# ESP32C3 register map
File version: 1.0
CPU: RISC-V RV32IMC single-core 1, little endian, no MPU, FPU, 3 interrupt priority bits
Registers are 32-bit, read-write, reset 0x0 unless marked. A register's access mark holds for its fields unless they carry their own. Offsets are from the block's base; [hi:lo] are bit positions; {n}, {i} and the like mark numbered series.

## I2C
Base 0x00000000
0x00 I2C_SCL_LOW_PERIOD
  [8:0] I2C_SCL_LOW_PERIOD
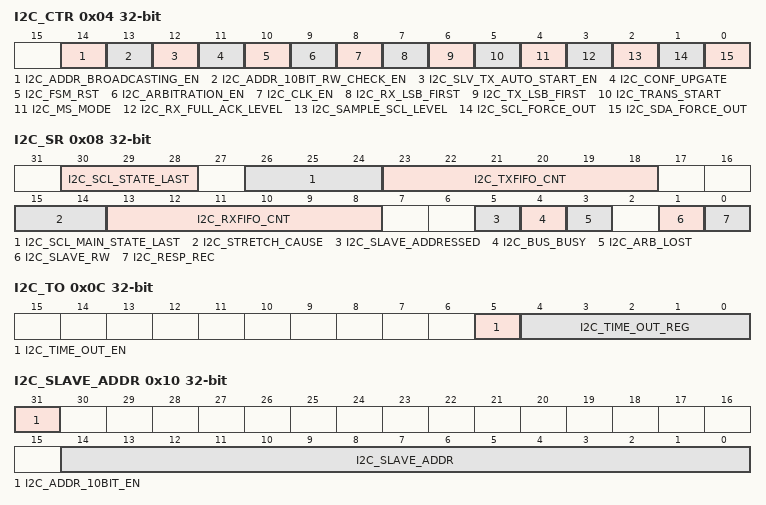
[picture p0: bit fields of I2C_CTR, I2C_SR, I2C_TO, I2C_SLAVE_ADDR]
0x04 I2C_CTR access per field
  [14] I2C_ADDR_BROADCASTING_EN rw, [13] I2C_ADDR_10BIT_RW_CHECK_EN rw, [12] I2C_SLV_TX_AUTO_START_EN rw, [11] I2C_CONF_UPGATE wo, [10] I2C_FSM_RST wo, [9] I2C_ARBITRATION_EN rw, [8] I2C_CLK_EN rw, [7] I2C_RX_LSB_FIRST rw, [6] I2C_TX_LSB_FIRST rw, [5] I2C_TRANS_START wo, [4] I2C_MS_MODE rw, [3] I2C_RX_FULL_ACK_LEVEL rw, [2] I2C_SAMPLE_SCL_LEVEL rw, [1] I2C_SCL_FORCE_OUT rw, [0] I2C_SDA_FORCE_OUT rw
0x08 I2C_SR ro
  [30:28] I2C_SCL_STATE_LAST, [26:24] I2C_SCL_MAIN_STATE_LAST, [23:18] I2C_TXFIFO_CNT, [15:14] I2C_STRETCH_CAUSE, [13:8] I2C_RXFIFO_CNT, [5] I2C_SLAVE_ADDRESSED, [4] I2C_BUS_BUSY, [3] I2C_ARB_LOST, [1] I2C_SLAVE_RW, [0] I2C_RESP_REC
0x0C I2C_TO
  [5] I2C_TIME_OUT_EN, [4:0] I2C_TIME_OUT_REG
0x10 I2C_SLAVE_ADDR
  [31] I2C_ADDR_10BIT_EN, [14:0] I2C_SLAVE_ADDR
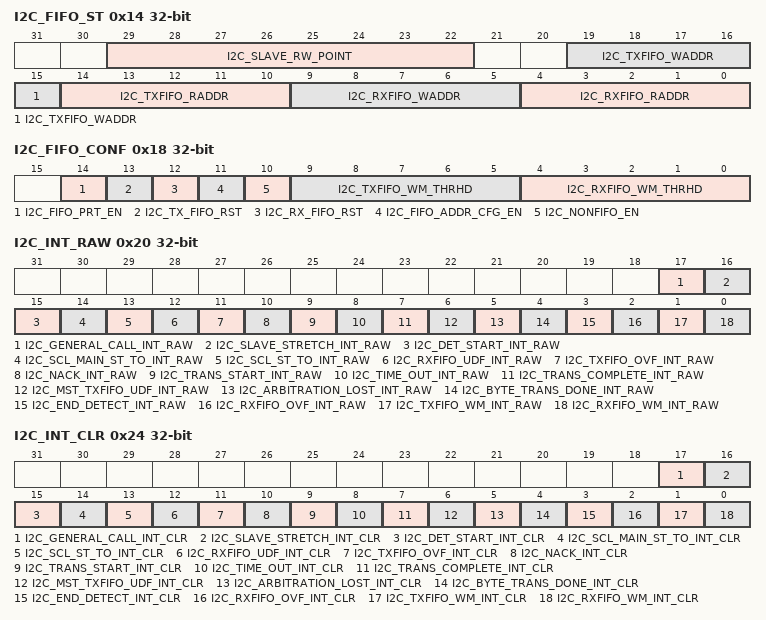
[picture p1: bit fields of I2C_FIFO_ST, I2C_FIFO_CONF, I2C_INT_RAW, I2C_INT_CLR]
0x14 I2C_FIFO_ST ro
  [29:22] I2C_SLAVE_RW_POINT, [19:15] I2C_TXFIFO_WADDR, [14:10] I2C_TXFIFO_RADDR, [9:5] I2C_RXFIFO_WADDR, [4:0] I2C_RXFIFO_RADDR
0x18 I2C_FIFO_CONF
  [14] I2C_FIFO_PRT_EN, [13] I2C_TX_FIFO_RST, [12] I2C_RX_FIFO_RST, [11] I2C_FIFO_ADDR_CFG_EN, [10] I2C_NONFIFO_EN, [9:5] I2C_TXFIFO_WM_THRHD, [4:0] I2C_RXFIFO_WM_THRHD
0x1C I2C_DATA ro
  [7:0] I2C_FIFO_RDATA
0x20 I2C_INT_RAW
  [17] I2C_GENERAL_CALL_INT_RAW, [16] I2C_SLAVE_STRETCH_INT_RAW, [15] I2C_DET_START_INT_RAW, [14] I2C_SCL_MAIN_ST_TO_INT_RAW, [13] I2C_SCL_ST_TO_INT_RAW, [12] I2C_RXFIFO_UDF_INT_RAW, [11] I2C_TXFIFO_OVF_INT_RAW, [10] I2C_NACK_INT_RAW, [9] I2C_TRANS_START_INT_RAW, [8] I2C_TIME_OUT_INT_RAW, [7] I2C_TRANS_COMPLETE_INT_RAW, [6] I2C_MST_TXFIFO_UDF_INT_RAW, [5] I2C_ARBITRATION_LOST_INT_RAW, [4] I2C_BYTE_TRANS_DONE_INT_RAW, [3] I2C_END_DETECT_INT_RAW, [2] I2C_RXFIFO_OVF_INT_RAW, [1] I2C_TXFIFO_WM_INT_RAW, [0] I2C_RXFIFO_WM_INT_RAW
0x24 I2C_INT_CLR wo
  [17] I2C_GENERAL_CALL_INT_CLR, [16] I2C_SLAVE_STRETCH_INT_CLR, [15] I2C_DET_START_INT_CLR, [14] I2C_SCL_MAIN_ST_TO_INT_CLR, [13] I2C_SCL_ST_TO_INT_CLR, [12] I2C_RXFIFO_UDF_INT_CLR, [11] I2C_TXFIFO_OVF_INT_CLR, [10] I2C_NACK_INT_CLR, [9] I2C_TRANS_START_INT_CLR, [8] I2C_TIME_OUT_INT_CLR, [7] I2C_TRANS_COMPLETE_INT_CLR, [6] I2C_MST_TXFIFO_UDF_INT_CLR, [5] I2C_ARBITRATION_LOST_INT_CLR, [4] I2C_BYTE_TRANS_DONE_INT_CLR, [3] I2C_END_DETECT_INT_CLR, [2] I2C_RXFIFO_OVF_INT_CLR, [1] I2C_TXFIFO_WM_INT_CLR, [0] I2C_RXFIFO_WM_INT_CLR
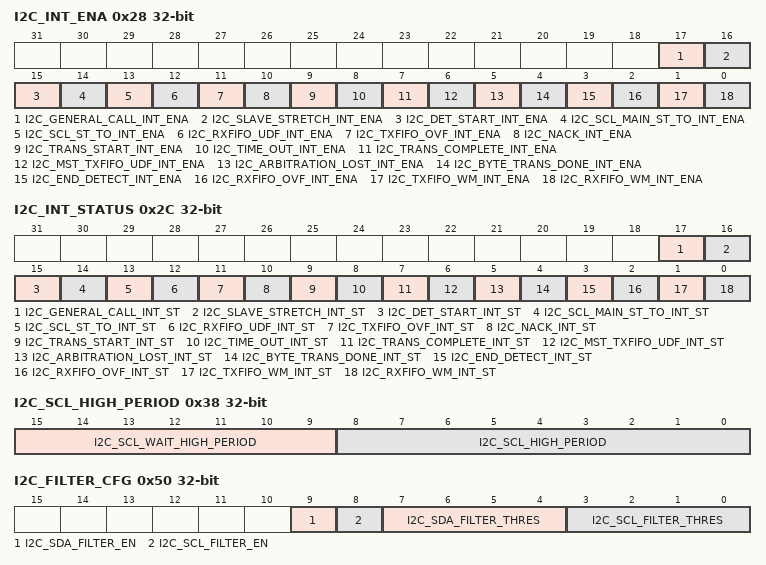
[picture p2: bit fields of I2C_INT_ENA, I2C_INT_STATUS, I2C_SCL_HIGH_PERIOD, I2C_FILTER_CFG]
0x28 I2C_INT_ENA
  [17] I2C_GENERAL_CALL_INT_ENA, [16] I2C_SLAVE_STRETCH_INT_ENA, [15] I2C_DET_START_INT_ENA, [14] I2C_SCL_MAIN_ST_TO_INT_ENA, [13] I2C_SCL_ST_TO_INT_ENA, [12] I2C_RXFIFO_UDF_INT_ENA, [11] I2C_TXFIFO_OVF_INT_ENA, [10] I2C_NACK_INT_ENA, [9] I2C_TRANS_START_INT_ENA, [8] I2C_TIME_OUT_INT_ENA, [7] I2C_TRANS_COMPLETE_INT_ENA, [6] I2C_MST_TXFIFO_UDF_INT_ENA, [5] I2C_ARBITRATION_LOST_INT_ENA, [4] I2C_BYTE_TRANS_DONE_INT_ENA, [3] I2C_END_DETECT_INT_ENA, [2] I2C_RXFIFO_OVF_INT_ENA, [1] I2C_TXFIFO_WM_INT_ENA, [0] I2C_RXFIFO_WM_INT_ENA
0x2C I2C_INT_STATUS ro
  [17] I2C_GENERAL_CALL_INT_ST, [16] I2C_SLAVE_STRETCH_INT_ST, [15] I2C_DET_START_INT_ST, [14] I2C_SCL_MAIN_ST_TO_INT_ST, [13] I2C_SCL_ST_TO_INT_ST, [12] I2C_RXFIFO_UDF_INT_ST, [11] I2C_TXFIFO_OVF_INT_ST, [10] I2C_NACK_INT_ST, [9] I2C_TRANS_START_INT_ST, [8] I2C_TIME_OUT_INT_ST, [7] I2C_TRANS_COMPLETE_INT_ST, [6] I2C_MST_TXFIFO_UDF_INT_ST, [5] I2C_ARBITRATION_LOST_INT_ST, [4] I2C_BYTE_TRANS_DONE_INT_ST, [3] I2C_END_DETECT_INT_ST, [2] I2C_RXFIFO_OVF_INT_ST, [1] I2C_TXFIFO_WM_INT_ST, [0] I2C_RXFIFO_WM_INT_ST
0x30 I2C_SDA_HOLD
  [8:0] I2C_SDA_HOLD_TIME
0x34 I2C_SDA_SAMPLE
  [8:0] I2C_SDA_SAMPLE_TIME
0x38 I2C_SCL_HIGH_PERIOD
  [15:9] I2C_SCL_WAIT_HIGH_PERIOD, [8:0] I2C_SCL_HIGH_PERIOD
0x40 I2C_SCL_START_HOLD
  [8:0] I2C_SCL_START_HOLD_TIME
0x44 I2C_SCL_RSTART_SETUP
  [8:0] I2C_SCL_RSTART_SETUP_TIME
0x48 I2C_SCL_STOP_HOLD
  [8:0] I2C_SCL_STOP_HOLD_TIME
0x4C I2C_SCL_STOP_SETUP
  [8:0] I2C_SCL_STOP_SETUP_TIME
0x50 I2C_FILTER_CFG
  [9] I2C_SDA_FILTER_EN, [8] I2C_SCL_FILTER_EN, [7:4] I2C_SDA_FILTER_THRES, [3:0] I2C_SCL_FILTER_THRES
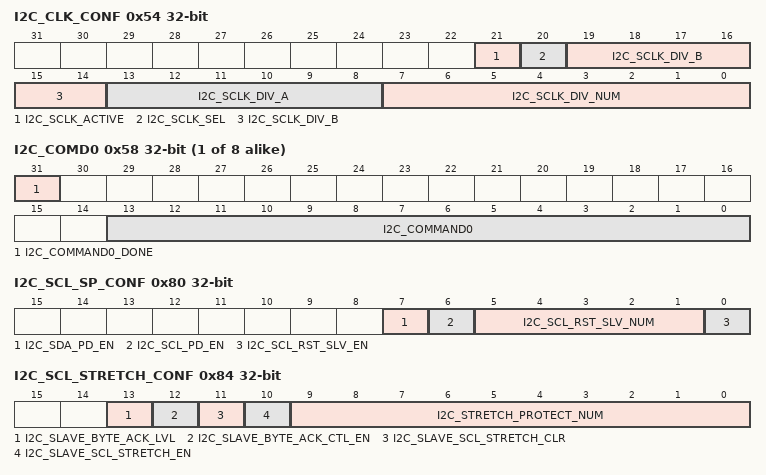
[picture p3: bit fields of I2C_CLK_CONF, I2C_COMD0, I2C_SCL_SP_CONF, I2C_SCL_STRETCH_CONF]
0x54 I2C_CLK_CONF
  [21] I2C_SCLK_ACTIVE, [20] I2C_SCLK_SEL, [19:14] I2C_SCLK_DIV_B, [13:8] I2C_SCLK_DIV_A, [7:0] I2C_SCLK_DIV_NUM
{0x58+4i} I2C_COMD{i} (i=0..7)
  [31] I2C_COMMAND{i}_DONE, [13:0] I2C_COMMAND{i}
0x78 I2C_SCL_ST_TIME_OUT
  [4:0] I2C_SCL_ST_TO_REG
0x7C I2C_SCL_MAIN_ST_TIME_OUT
  [4:0] I2C_SCL_MAIN_ST_TO_REG
0x80 I2C_SCL_SP_CONF
  [7] I2C_SDA_PD_EN, [6] I2C_SCL_PD_EN, [5:1] I2C_SCL_RST_SLV_NUM, [0] I2C_SCL_RST_SLV_EN
0x84 I2C_SCL_STRETCH_CONF access per field
  [13] I2C_SLAVE_BYTE_ACK_LVL rw, [12] I2C_SLAVE_BYTE_ACK_CTL_EN rw, [11] I2C_SLAVE_SCL_STRETCH_CLR wo, [10] I2C_SLAVE_SCL_STRETCH_EN rw, [9:0] I2C_STRETCH_PROTECT_NUM rw
0xF8 I2C_DATE
